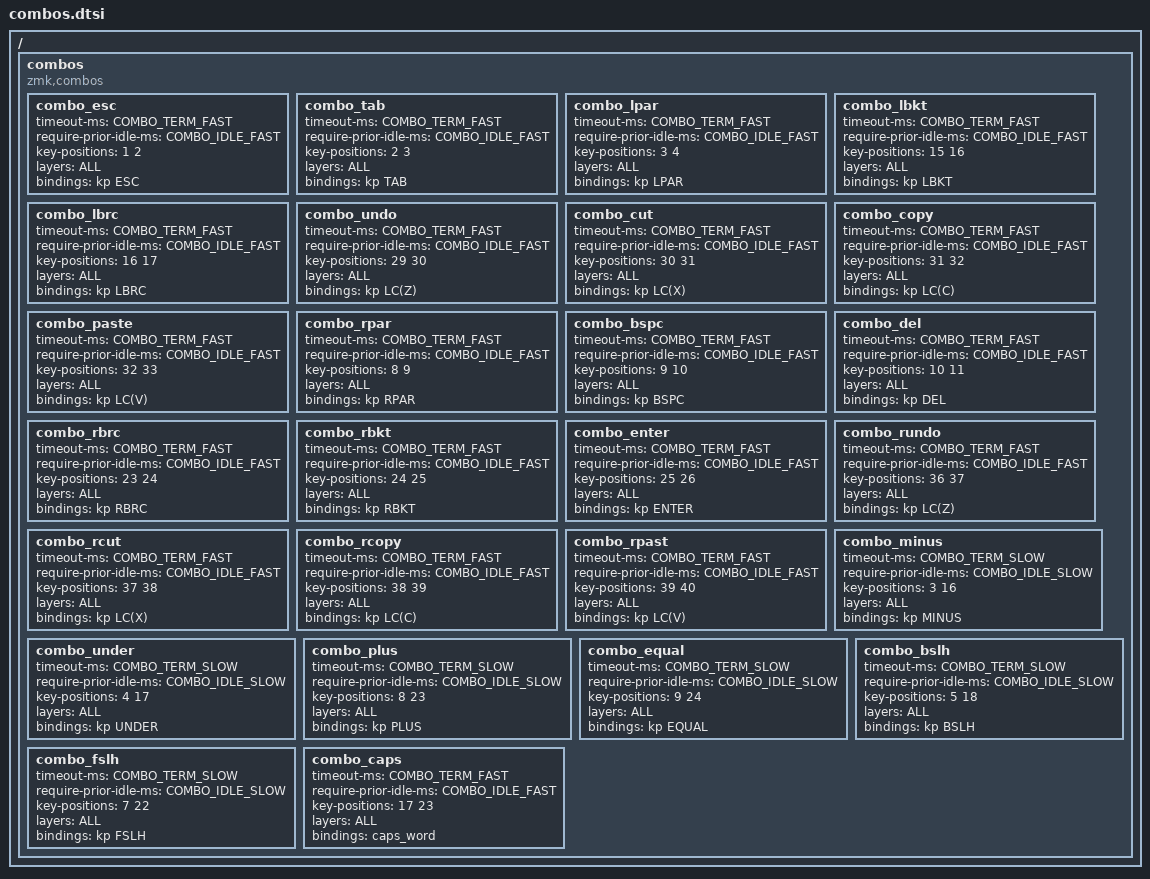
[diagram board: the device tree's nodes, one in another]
/* Timing definitions from urob's config */
#define COMBO_TERM_FAST 35
#define COMBO_TERM_SLOW 40
#define COMBO_IDLE_FAST 150
#define COMBO_IDLE_SLOW 50

#define ALL DEF NAV NUM FN

/ {
  combos {
    compatible = "zmk,combos";

    /* =========================================================================
     * Left-Hand Horizontal Combos (Shortcuts & Left Brackets)
     * ========================================================================= */
    combo_esc   { timeout-ms = <COMBO_TERM_FAST>; require-prior-idle-ms = <COMBO_IDLE_FAST>; key-positions = <1 2>;   layers = <ALL>; bindings = <&kp ESC>; };       // Q + W
    combo_tab   { timeout-ms = <COMBO_TERM_FAST>; require-prior-idle-ms = <COMBO_IDLE_FAST>; key-positions = <2 3>;   layers = <ALL>; bindings = <&kp TAB>; };       // W + E
    combo_lpar  { timeout-ms = <COMBO_TERM_FAST>; require-prior-idle-ms = <COMBO_IDLE_FAST>; key-positions = <3 4>;   layers = <ALL>; bindings = <&kp LPAR>; };      // E + R -> (
    combo_lbkt  { timeout-ms = <COMBO_TERM_FAST>; require-prior-idle-ms = <COMBO_IDLE_FAST>; key-positions = <15 16>; layers = <ALL>; bindings = <&kp LBKT>; };      // S + D -> [
    combo_lbrc  { timeout-ms = <COMBO_TERM_FAST>; require-prior-idle-ms = <COMBO_IDLE_FAST>; key-positions = <16 17>; layers = <ALL>; bindings = <&kp LBRC>; };      // D + F -> {
    combo_undo  { timeout-ms = <COMBO_TERM_FAST>; require-prior-idle-ms = <COMBO_IDLE_FAST>; key-positions = <29 30>; layers = <ALL>; bindings = <&kp LC(Z)>; };    // Z + X -> Undo
    combo_cut   { timeout-ms = <COMBO_TERM_FAST>; require-prior-idle-ms = <COMBO_IDLE_FAST>; key-positions = <30 31>; layers = <ALL>; bindings = <&kp LC(X)>; };    // X + C -> Cut
    combo_copy  { timeout-ms = <COMBO_TERM_FAST>; require-prior-idle-ms = <COMBO_IDLE_FAST>; key-positions = <31 32>; layers = <ALL>; bindings = <&kp LC(C)>; };    // C + V -> Copy
    combo_paste { timeout-ms = <COMBO_TERM_FAST>; require-prior-idle-ms = <COMBO_IDLE_FAST>; key-positions = <32 33>; layers = <ALL>; bindings = <&kp LC(V)>; };    // V + B -> Paste

    /* =========================================================================
     * Right-Hand Horizontal Combos (Right Brackets & Left-Hand Mouse Helpers!)
     * ========================================================================= */
    combo_rpar  { timeout-ms = <COMBO_TERM_FAST>; require-prior-idle-ms = <COMBO_IDLE_FAST>; key-positions = <8 9>;   layers = <ALL>; bindings = <&kp RPAR>; };      // U + I -> )
    combo_bspc  { timeout-ms = <COMBO_TERM_FAST>; require-prior-idle-ms = <COMBO_IDLE_FAST>; key-positions = <9 10>;  layers = <ALL>; bindings = <&kp BSPC>; };      // I + O -> Backspace
    combo_del   { timeout-ms = <COMBO_TERM_FAST>; require-prior-idle-ms = <COMBO_IDLE_FAST>; key-positions = <10 11>; layers = <ALL>; bindings = <&kp DEL>; };       // O + P -> Delete
    combo_rbrc  { timeout-ms = <COMBO_TERM_FAST>; require-prior-idle-ms = <COMBO_IDLE_FAST>; key-positions = <23 24>; layers = <ALL>; bindings = <&kp RBRC>; };      // J + K -> }
    combo_rbkt  { timeout-ms = <COMBO_TERM_FAST>; require-prior-idle-ms = <COMBO_IDLE_FAST>; key-positions = <24 25>; layers = <ALL>; bindings = <&kp RBKT>; };      // K + L -> ]
    combo_enter { timeout-ms = <COMBO_TERM_FAST>; require-prior-idle-ms = <COMBO_IDLE_FAST>; key-positions = <25 26>; layers = <ALL>; bindings = <&kp ENTER>; };     // L + ; -> Enter
    combo_rundo { timeout-ms = <COMBO_TERM_FAST>; require-prior-idle-ms = <COMBO_IDLE_FAST>; key-positions = <36 37>; layers = <ALL>; bindings = <&kp LC(Z)>; };    // N + M -> Undo (Right Hand)
    combo_rcut  { timeout-ms = <COMBO_TERM_FAST>; require-prior-idle-ms = <COMBO_IDLE_FAST>; key-positions = <37 38>; layers = <ALL>; bindings = <&kp LC(X)>; };    // M + , -> Cut (Right Hand)
    combo_rcopy { timeout-ms = <COMBO_TERM_FAST>; require-prior-idle-ms = <COMBO_IDLE_FAST>; key-positions = <38 39>; layers = <ALL>; bindings = <&kp LC(C)>; };    // , + . -> Copy (Right Hand)
    combo_rpast { timeout-ms = <COMBO_TERM_FAST>; require-prior-idle-ms = <COMBO_IDLE_FAST>; key-positions = <39 40>; layers = <ALL>; bindings = <&kp LC(V)>; };    // . + / -> Paste (Right Hand)

    /* =========================================================================
     * Vertical Combos (Punctuation & Symbols)
     * ========================================================================= */
    combo_minus { timeout-ms = <COMBO_TERM_SLOW>; require-prior-idle-ms = <COMBO_IDLE_SLOW>; key-positions = <3 16>;  layers = <ALL>; bindings = <&kp MINUS>; };     // E + D -> -
    combo_under { timeout-ms = <COMBO_TERM_SLOW>; require-prior-idle-ms = <COMBO_IDLE_SLOW>; key-positions = <4 17>;  layers = <ALL>; bindings = <&kp UNDER>; };     // R + F -> _
    combo_plus  { timeout-ms = <COMBO_TERM_SLOW>; require-prior-idle-ms = <COMBO_IDLE_SLOW>; key-positions = <8 23>;  layers = <ALL>; bindings = <&kp PLUS>; };      // U + J -> +
    combo_equal { timeout-ms = <COMBO_TERM_SLOW>; require-prior-idle-ms = <COMBO_IDLE_SLOW>; key-positions = <9 24>;  layers = <ALL>; bindings = <&kp EQUAL>; };     // I + K -> =
    combo_bslh  { timeout-ms = <COMBO_TERM_SLOW>; require-prior-idle-ms = <COMBO_IDLE_SLOW>; key-positions = <5 18>;  layers = <ALL>; bindings = <&kp BSLH>; };      // T + G -> \
    combo_fslh  { timeout-ms = <COMBO_TERM_SLOW>; require-prior-idle-ms = <COMBO_IDLE_SLOW>; key-positions = <7 22>;  layers = <ALL>; bindings = <&kp FSLH>; };      // Y + H -> /

    /* =========================================================================
     * Special Combos
     * ========================================================================= */
    combo_caps  { timeout-ms = <COMBO_TERM_FAST>; require-prior-idle-ms = <COMBO_IDLE_FAST>; key-positions = <17 23>; layers = <ALL>; bindings = <&caps_word>; };   // F + J -> Caps Word
  };
};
